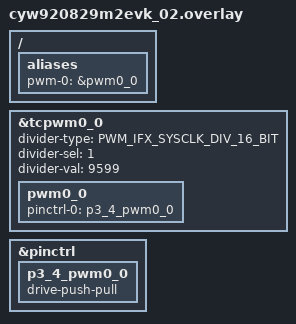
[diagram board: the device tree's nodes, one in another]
/*
 * Copyright (c) 2025 Infineon Technologies AG,
 * or an affiliate of Infineon Technologies AG.
 *
 * SPDX-License-Identifier: Apache-2.0
 */

#include <zephyr/dt-bindings/pwm/pwm.h>
#include <zephyr/dt-bindings/pwm/pwm_ifx_tcpwm.h>

/ {
	aliases {
		pwm-0 = &pwm0_0;
	};
};

&tcpwm0_0 {
	status = "okay";
	divider-type = <PWM_IFX_SYSCLK_DIV_16_BIT>;
	divider-sel = <1>;
	divider-val = <9599>;

	pwm0_0: pwm0_0 {
		status = "okay";
		pinctrl-0 = <&p3_4_pwm0_0>;
		pinctrl-names = "default";
	};
};

&pinctrl {
	p3_4_pwm0_0: p3_4_pwm0_0 {
		drive-push-pull;
	};
};
